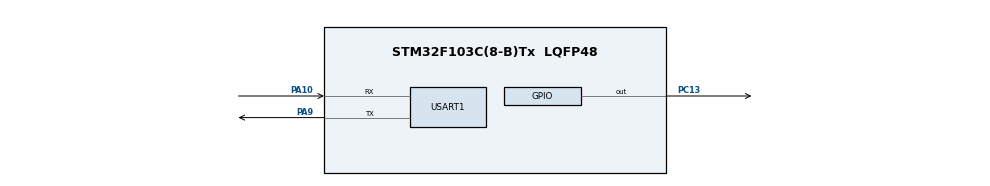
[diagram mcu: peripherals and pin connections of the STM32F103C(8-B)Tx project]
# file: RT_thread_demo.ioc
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Mcu.Family=STM32F1
Mcu.Name=STM32F103C(8-B)Tx
Mcu.Package=LQFP48
NVIC.PriorityGroup=NVIC_PRIORITYGROUP_4
PA10.Mode=Asynchronous
PA10.Signal=USART1_RX
PA13.Mode=Serial_Wire
PA13.Signal=SYS_JTMS-SWDIO
PA14.Mode=Serial_Wire
PA14.Signal=SYS_JTCK-SWCLK
PA9.Mode=Asynchronous
PA9.Signal=USART1_TX
PC13-TAMPER-RTC.Signal=GPIO_Output
ProjectManager.HeapSize=0x200
ProjectManager.StackSize=0x400
ProjectManager.TargetToolchain=MDK-ARM V5.32
RCC.APB1Freq_Value=8000000
RCC.APB2Freq_Value=8000000
RealThread.RT-Thread.3.1.5.RTOSJjkernel=true
RealThread.RT-Thread.3.1.5.RTOSJjshell=true
USART1.VirtualMode=VM_ASYNC
VP_RealThread.RT-Thread_VS_RTOSJjkernel_3.1.5_3.1.5.Mode=RTOSJjkernel
VP_RealThread.RT-Thread_VS_RTOSJjshell_3.1.5_3.1.5.Mode=RTOSJjshell
board=custom

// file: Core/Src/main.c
/* USER CODE BEGIN Header */
/**
  ******************************************************************************
  * @file           : main.c
  * @brief          : Main program body
  ******************************************************************************
  * @attention
  *
  * Copyright (c) 2023 STMicroelectronics.
  * All rights reserved.
  *
  * This software is licensed under terms that can be found in the LICENSE file
  * in the root directory of this software component.
  * If no LICENSE file comes with this software, it is provided AS-IS.
  *
  ******************************************************************************
  */
/* USER CODE END Header */
#include "main.h"
#include "usart.h"
#include "gpio.h"

/* USER CODE BEGIN Includes */
#include <rtthread.h>

/* USER CODE END Includes */

void SystemClock_Config(void);

/* USER CODE BEGIN 0 */
void send_data(void *promt){

  while (1)
  {
    rt_thread_mdelay(1000);
    HAL_UART_Transmit(&huart1,(uint8_t*)"你好RT_thread!\r\n",rt_strlen("你好RT_thread!\r\n"),0xffff);
  }

}
/* USER CODE END 0 */

int main(void)
{

  /* MCU Configuration--------------------------------------------------------*/

  /* Reset of all peripherals, Initializes the Flash interface and the Systick. */
  HAL_Init();

  /* Configure the system clock */
  SystemClock_Config();

  /* Initialize all configured peripherals */
  MX_GPIO_Init();
  MX_USART1_UART_Init();
  /* USER CODE BEGIN 2 */

    /* 创建线程 */
    rt_thread_t usart_task_tid = rt_thread_create("send_data",/* 线程名称 */
                            send_data, RT_NULL,
                            1024, 3, 10); //
    if(usart_task_tid != RT_NULL)
    {
        /* 启动线程 */
        rt_thread_startup(usart_task_tid);
        rt_kprintf("usart thread is already started\n");

    }
    else
    {
        rt_kprintf("usart thread is not started\n");
    }
  /* USER CODE END 2 */

  /* Infinite loop */
  /* USER CODE BEGIN WHILE */
  while (1)
  {
    /* USER CODE BEGIN 3 */
    HAL_GPIO_WritePin(GPIOC,GPIO_PIN_13,GPIO_PIN_RESET);
		rt_thread_mdelay(1000);
    HAL_GPIO_WritePin(GPIOC,GPIO_PIN_13,GPIO_PIN_SET);
		rt_thread_mdelay(1000);
    /* USER CODE END 3 */
  }
	/* USER CODE END WHILE */

}

void SystemClock_Config(void)
{
  RCC_OscInitTypeDef RCC_OscInitStruct = {0};
  RCC_ClkInitTypeDef RCC_ClkInitStruct = {0};

  /** Initializes the RCC Oscillators according to the specified parameters
  * in the RCC_OscInitTypeDef structure.
  */
  RCC_OscInitStruct.OscillatorType = RCC_OSCILLATORTYPE_HSI;
  RCC_OscInitStruct.HSIState = RCC_HSI_ON;
  RCC_OscInitStruct.HSICalibrationValue = RCC_HSICALIBRATION_DEFAULT;
  RCC_OscInitStruct.PLL.PLLState = RCC_PLL_NONE;
  if (HAL_RCC_OscConfig(&RCC_OscInitStruct) != HAL_OK)
  {
    Error_Handler();
  }

  /** Initializes the CPU, AHB and APB buses clocks
  */
  RCC_ClkInitStruct.ClockType = RCC_CLOCKTYPE_HCLK|RCC_CLOCKTYPE_SYSCLK
                              |RCC_CLOCKTYPE_PCLK1|RCC_CLOCKTYPE_PCLK2;
  RCC_ClkInitStruct.SYSCLKSource = RCC_SYSCLKSOURCE_HSI;
  RCC_ClkInitStruct.AHBCLKDivider = RCC_SYSCLK_DIV1;
  RCC_ClkInitStruct.APB1CLKDivider = RCC_HCLK_DIV1;
  RCC_ClkInitStruct.APB2CLKDivider = RCC_HCLK_DIV1;

  if (HAL_RCC_ClockConfig(&RCC_ClkInitStruct, FLASH_LATENCY_0) != HAL_OK)
  {
    Error_Handler();
  }
}

void Error_Handler(void)
{
  __disable_irq();
  while (1)
  {
  }
}
